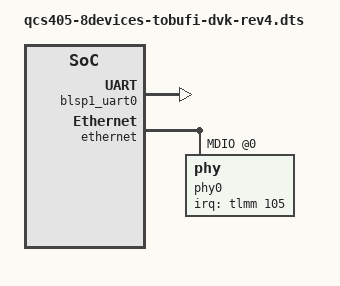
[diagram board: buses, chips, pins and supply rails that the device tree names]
// SPDX-License-Identifier: GPL-2.0
/*
 * Copyright (c) 2025 8devices, UAB
 */

/dts-v1/;

#include <dt-bindings/interrupt-controller/irq.h>
#include "qcs405-8devices-tobufi-dvk.dts"

/ {
	/* IOT (0x20) TobuFi-DVK (0x81) HWrev (4.0) */
	qcom,board-id = <0x81000420 0x0>;

	aliases {
		serial0 = &blsp1_uart2;
		serial1 = &blsp1_uart0;
		serial2 = &blsp1_uart1;
		serial3 = &blsp2_uart0;
	};
};

&tlmm {
	phy_int_default: phy-int-default-state {
		pins = "gpio105";
		function = "gpio";
		bias-disable;
		input-enable;
	};
};

/* BLSP0, 4-pin connector */
&blsp1_uart0 {
	status = "okay";
};

&ethernet {
	mdio {
		phy0: phy@0 {
			interrupt-parent = <&tlmm>;
			interrupts = <105 IRQ_TYPE_LEVEL_LOW>;
			pinctrl-names = "default";
			pinctrl-0 = <&phy_int_default>;
		};
	};
};
